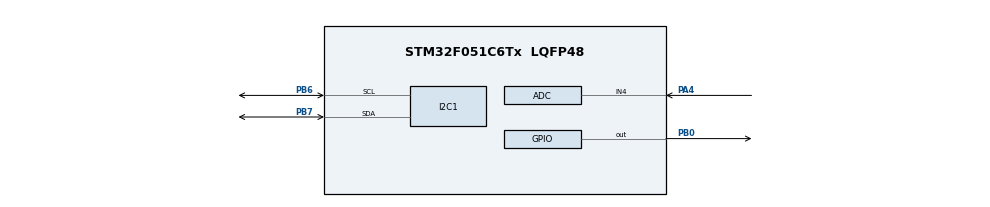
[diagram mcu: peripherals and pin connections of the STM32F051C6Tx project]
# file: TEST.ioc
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Mcu.Family=STM32F0
Mcu.Name=STM32F051C6Tx
Mcu.Package=LQFP48
PA4.Mode=IN4
PA4.Signal=ADC_IN4
PB0.Signal=GPIO_Output
PB6.Mode=I2C
PB6.Signal=I2C1_SCL
PB7.Mode=I2C
PB7.Signal=I2C1_SDA
ProjectManager.HeapSize=0x200
ProjectManager.StackSize=0x400
ProjectManager.TargetToolchain=STM32CubeIDE
board=custom

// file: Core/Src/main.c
/* USER CODE BEGIN Header */
/**
  ******************************************************************************
  * @file           : main.c
  * @brief          : Main program body
  ******************************************************************************
  * @attention
  *
  * Copyright (c) 2023 STMicroelectronics.
  * All rights reserved.
  *
  * This software is licensed under terms that can be found in the LICENSE file
  * in the root directory of this software component.
  * If no LICENSE file comes with this software, it is provided AS-IS.
  *
  ******************************************************************************
  */
/* USER CODE END Header */
#include "main.h"

ADC_HandleTypeDef hadc;

I2C_HandleTypeDef hi2c1;

/* USER CODE BEGIN PV */
uint8_t datawrite[16] = "Hello EEPROM";

uint8_t datared [17];

ADC_HandleTypeDef *hadcP = &hadc;

uint16_t adcValue;

HAL_StatusTypeDef status;

//uint8_t *dataredPointer = &datared;

//uint16_t EEPROM_DEVICE_ADDR = 0x55 << 1; //Address of EEPROM device on I2C bus//might have <<1 cos we are writing/reading
uint16_t EEPROM_DEVICE_ADDR = 0;
uint16_t madd = 0x00; //Memory address variable containing a starting memory address for a location of memory in the EEPROM
HAL_StatusTypeDef statusWrite;
/* USER CODE END PV */

void SystemClock_Config(void);
static void MX_GPIO_Init(void);
static void MX_I2C1_Init(void);
static void MX_ADC_Init(void);

int main(void)
{

  /* MCU Configuration--------------------------------------------------------*/

  /* Reset of all peripherals, Initializes the Flash interface and the Systick. */
  HAL_Init();

  /* Configure the system clock */
  SystemClock_Config();

  /* Initialize all configured peripherals */
  MX_GPIO_Init();
  MX_I2C1_Init();
  MX_ADC_Init();
  /* USER CODE BEGIN 2 */
  HAL_ADC_Start (hadcP) ;
  /* USER CODE END 2 */

  /* Infinite loop */
  /* USER CODE BEGIN WHILE */
  while (1)
  {
	  if( HAL_ADC_PollForConversion(&hadc, 10000000)== HAL_OK)
	  	  					{

	  	  					adcValue =  HAL_ADC_GetValue(&hadc);

	  	  					if(adcValue>0){
	  	  					HAL_GPIO_TogglePin(GPIOB,GPIO_PIN_0);

	  	  						HAL_Delay(100);
	  	  						}
	  	  					}
	 /// statusWrite = HAL_I2C_Mem_Write(&hi2c1, EEPROM_DEVICE_ADDR, madd, 2, datawrite, 11, HAL_MAX_DELAY);

	   //status = HAL_I2C_Mem_Read(&hi2c1, EEPROM_DEVICE_ADDR, madd, 2,datared, sizeof(datared), HAL_MAX_DELAY);

    /* USER CODE END WHILE */

  }
}

void SystemClock_Config(void)
{
  RCC_OscInitTypeDef RCC_OscInitStruct = {0};
  RCC_ClkInitTypeDef RCC_ClkInitStruct = {0};
  RCC_PeriphCLKInitTypeDef PeriphClkInit = {0};

  /** Initializes the RCC Oscillators according to the specified parameters
  * in the RCC_OscInitTypeDef structure.
  */
  RCC_OscInitStruct.OscillatorType = RCC_OSCILLATORTYPE_HSI|RCC_OSCILLATORTYPE_HSI14;
  RCC_OscInitStruct.HSIState = RCC_HSI_ON;
  RCC_OscInitStruct.HSI14State = RCC_HSI14_ON;
  RCC_OscInitStruct.HSICalibrationValue = RCC_HSICALIBRATION_DEFAULT;
  RCC_OscInitStruct.HSI14CalibrationValue = 16;
  RCC_OscInitStruct.PLL.PLLState = RCC_PLL_NONE;
  if (HAL_RCC_OscConfig(&RCC_OscInitStruct) != HAL_OK)
  {
    Error_Handler();
  }

  /** Initializes the CPU, AHB and APB buses clocks
  */
  RCC_ClkInitStruct.ClockType = RCC_CLOCKTYPE_HCLK|RCC_CLOCKTYPE_SYSCLK
                              |RCC_CLOCKTYPE_PCLK1;
  RCC_ClkInitStruct.SYSCLKSource = RCC_SYSCLKSOURCE_HSI;
  RCC_ClkInitStruct.AHBCLKDivider = RCC_SYSCLK_DIV1;
  RCC_ClkInitStruct.APB1CLKDivider = RCC_HCLK_DIV1;

  if (HAL_RCC_ClockConfig(&RCC_ClkInitStruct, FLASH_LATENCY_0) != HAL_OK)
  {
    Error_Handler();
  }
  PeriphClkInit.PeriphClockSelection = RCC_PERIPHCLK_I2C1;
  PeriphClkInit.I2c1ClockSelection = RCC_I2C1CLKSOURCE_HSI;
  if (HAL_RCCEx_PeriphCLKConfig(&PeriphClkInit) != HAL_OK)
  {
    Error_Handler();
  }
}

static void MX_ADC_Init(void)
{

  ADC_ChannelConfTypeDef sConfig = {0};

  /** Configure the global features of the ADC (Clock, Resolution, Data Alignment and number of conversion)
  */
  hadc.Instance = ADC1;
  hadc.Init.ClockPrescaler = ADC_CLOCK_ASYNC_DIV1;
  hadc.Init.Resolution = ADC_RESOLUTION_12B;
  hadc.Init.DataAlign = ADC_DATAALIGN_RIGHT;
  hadc.Init.ScanConvMode = ADC_SCAN_DIRECTION_FORWARD;
  hadc.Init.EOCSelection = ADC_EOC_SINGLE_CONV;
  hadc.Init.LowPowerAutoWait = DISABLE;
  hadc.Init.LowPowerAutoPowerOff = DISABLE;
  hadc.Init.ContinuousConvMode = DISABLE;
  hadc.Init.DiscontinuousConvMode = DISABLE;
  hadc.Init.ExternalTrigConv = ADC_SOFTWARE_START;
  hadc.Init.ExternalTrigConvEdge = ADC_EXTERNALTRIGCONVEDGE_NONE;
  hadc.Init.DMAContinuousRequests = DISABLE;
  hadc.Init.Overrun = ADC_OVR_DATA_PRESERVED;
  if (HAL_ADC_Init(&hadc) != HAL_OK)
  {
    Error_Handler();
  }

  /** Configure for the selected ADC regular channel to be converted.
  */
  sConfig.Channel = ADC_CHANNEL_4;
  sConfig.Rank = ADC_RANK_CHANNEL_NUMBER;
  sConfig.SamplingTime = ADC_SAMPLETIME_1CYCLE_5;
  if (HAL_ADC_ConfigChannel(&hadc, &sConfig) != HAL_OK)
  {
    Error_Handler();
  }

}

static void MX_I2C1_Init(void)
{

  hi2c1.Instance = I2C1;
  hi2c1.Init.Timing = 0x2000090E;
  hi2c1.Init.OwnAddress1 = 0;
  hi2c1.Init.AddressingMode = I2C_ADDRESSINGMODE_7BIT;
  hi2c1.Init.DualAddressMode = I2C_DUALADDRESS_DISABLE;
  hi2c1.Init.OwnAddress2 = 0;
  hi2c1.Init.OwnAddress2Masks = I2C_OA2_NOMASK;
  hi2c1.Init.GeneralCallMode = I2C_GENERALCALL_DISABLE;
  hi2c1.Init.NoStretchMode = I2C_NOSTRETCH_DISABLE;
  if (HAL_I2C_Init(&hi2c1) != HAL_OK)
  {
    Error_Handler();
  }

  /** Configure Analogue filter
  */
  if (HAL_I2CEx_ConfigAnalogFilter(&hi2c1, I2C_ANALOGFILTER_ENABLE) != HAL_OK)
  {
    Error_Handler();
  }

  /** Configure Digital filter
  */
  if (HAL_I2CEx_ConfigDigitalFilter(&hi2c1, 0) != HAL_OK)
  {
    Error_Handler();
  }

}

static void MX_GPIO_Init(void)
{
  GPIO_InitTypeDef GPIO_InitStruct = {0};

  /* GPIO Ports Clock Enable */
  __HAL_RCC_GPIOA_CLK_ENABLE();
  __HAL_RCC_GPIOB_CLK_ENABLE();

  /*Configure GPIO pin Output Level */
  HAL_GPIO_WritePin(GPIOB, GPIO_PIN_0, GPIO_PIN_RESET);

  /*Configure GPIO pin : PB0 */
  GPIO_InitStruct.Pin = GPIO_PIN_0;
  GPIO_InitStruct.Mode = GPIO_MODE_OUTPUT_PP;
  GPIO_InitStruct.Pull = GPIO_NOPULL;
  GPIO_InitStruct.Speed = GPIO_SPEED_FREQ_LOW;
  HAL_GPIO_Init(GPIOB, &GPIO_InitStruct);

}

void Error_Handler(void)
{
  __disable_irq();
  while (1)
  {
  }
}
